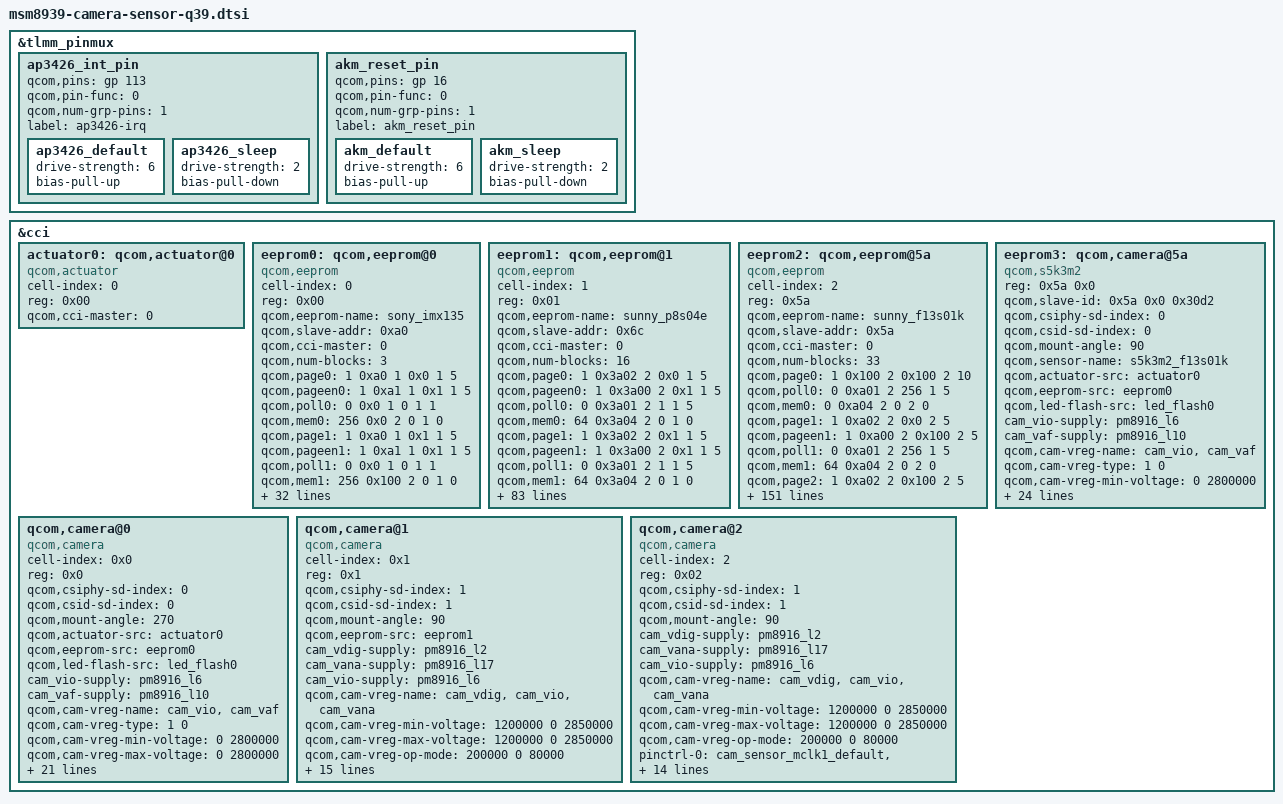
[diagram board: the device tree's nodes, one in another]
/* Copyright (c) 2017, The Linux Foundation. All rights reserved.
 *
 * This program is free software; you can redistribute it and/or modify
 * it under the terms of the GNU General Public License version 2 and
 * only version 2 as published by the Free Software Foundation.
 *
 * This program is distributed in the hope that it will be useful,
 * but WITHOUT ANY WARRANTY; without even the implied warranty of
 * MERCHANTABILITY or FITNESS FOR A PARTICULAR PURPOSE.  See the
 * GNU General Public License for more details.
 */

&tlmm_pinmux {
		ap3426_int_pin {
		qcom,pins = <&gp 113>;
		qcom,pin-func = <0>;
		qcom,num-grp-pins = <1>;
		label = "ap3426-irq";

		ap3426_default: ap3426_default {
			drive-strength = <6>;
			bias-pull-up;
			};

		ap3426_sleep: ap3426_sleep {
			drive-strength = <2>;
			bias-pull-down;
			};
		};

		akm_reset_pin {
			qcom,pins = <&gp 16>;
			qcom,pin-func = <0>;
			qcom,num-grp-pins = <1>;
			label = "akm_reset_pin";

			akm_default: akm_default {
				drive-strength = <6>;
				bias-pull-up;
			};

			akm_sleep: akm_sleep {
			drive-strength = <2>;
			bias-pull-down;
			};
		};
};

&cci {

		actuator0: qcom,actuator@0 {
			cell-index = <0>;
			reg = <0x00>;
			compatible = "qcom,actuator";
			qcom,cci-master = <0>;
		};

		eeprom0: qcom,eeprom@0 {
			cell-index = <0>;
			reg = <0x00>;
			qcom,eeprom-name = "sony_imx135";
			compatible = "qcom,eeprom";
			qcom,slave-addr = <0xa0>;
			qcom,cci-master = <0>;
			qcom,num-blocks = <3>;

			qcom,page0 = <1 0xa0 1 0x0 1 5>;
			qcom,pageen0 = <1 0xa1 1 0x1 1 5>;
			qcom,poll0 = <0 0x0 1 0 1 1>;
			qcom,mem0 = <256 0x0 2 0 1 0>;
			qcom,page1 = <1 0xa0 1 0x1 1 5>;
			qcom,pageen1 = <1 0xa1 1 0x1 1 5>;
			qcom,poll1 = <0 0x0 1 0 1 1>;
			qcom,mem1 = <256 0x100 2 0 1 0>;
			qcom,page2 = <1 0xa0 1 0x2 1 5>;
			qcom,pageen2 = <1 0xa1 1 0x1 1 5>;
			qcom,poll2 = <0 0x0 1 0 1 1>;
			qcom,mem2 = <23 0x200 2 0 1 0>;

			cam_vio-supply = <&pm8916_l2>;
			qcom,cam-vreg-name = "cam_vio";
			qcom,cam-vreg-min-voltage = <0>;
			qcom,cam-vreg-max-voltage = <0>;
			qcom,cam-vreg-op-mode = <0>;
			pinctrl-names = "cam_default", "cam_suspend";
			pinctrl-0 = <&cam_sensor_mclk0_default &cam_sensor_rear_default>;
			pinctrl-1 = <&cam_sensor_mclk0_sleep &cam_sensor_rear_sleep>;
			gpios = <&msm_gpio 26 0>,
				<&msm_gpio 35 0>,
				<&msm_gpio 2 0>,
				<&msm_gpio 3 0>;
			qcom,gpio-reset = <1>;
			qcom,gpio-vana = <2>;
			qcom,gpio-vdig = <3>;
			qcom,gpio-req-tbl-num = <0 1 2 3>;
			qcom,gpio-req-tbl-flags = <1 0 0 0>;
			qcom,gpio-req-tbl-label = "CAMIF_MCLK0",
				"CAM_RESET1",
				"CAM_VANA",
				"CAM_VDIG";

			qcom,cam-power-seq-type = "sensor_gpio",
				"sensor_gpio", "sensor_vreg",
				"sensor_clk", "sensor_gpio";
			qcom,cam-power-seq-val = "sensor_gpio_vana",
				"sensor_gpio_vdig", "cam_vio",
				"sensor_cam_mclk", "sensor_gpio_reset";
			qcom,cam-power-seq-cfg-val = <1 1 1 24000000 1>;
			qcom,cam-power-seq-delay = <1 1 5 5 10>;
			status = "ok";
			clocks = <&clock_gcc clk_mclk0_clk_src>,
				<&clock_gcc clk_gcc_camss_mclk0_clk>;
			clock-names = "cam_src_clk", "cam_clk";
		};

		eeprom1: qcom,eeprom@1 {
			cell-index = <1>;
			reg = <0x01>;
			qcom,eeprom-name = "sunny_p8s04e";
			compatible = "qcom,eeprom";
			qcom,slave-addr = <0x6c>;
			qcom,cci-master = <0>;

			qcom,num-blocks = <16>;
			qcom,page0 = <1 0x3a02 2 0x0 1 5>;
			qcom,pageen0 = <1 0x3a00 2 0x1 1 5>;
			qcom,poll0 = <0 0x3a01 2 1 1 5>;
			qcom,mem0 = <64 0x3a04 2 0 1 0>;
			qcom,page1 = <1 0x3a02 2 0x1 1 5>;
			qcom,pageen1 = <1 0x3a00 2 0x1 1 5>;
			qcom,poll1 = <0 0x3a01 2 1 1 5>;
			qcom,mem1 = <64 0x3a04 2 0 1 0>;
			qcom,page2 = <1 0x3a02 2 0x2 1 5>;
			qcom,pageen2 = <1 0x3a00 2 0x1 1 5>;
			qcom,poll2 = <0 0x3a01 2 1 1 5>;
			qcom,mem2 = <64 0x3a04 2 0 1 0>;
			qcom,page3 = <1 0x3a02 2 0x3 1 5>;
			qcom,pageen3 = <1 0x3a00 2 0x1 1 5>;
			qcom,poll3 = <0 0x3a01 2 1 1 5>;
			qcom,mem3 = <64 0x3a04 2 0 1 0>;
			qcom,page4 = <1 0x3a02 2 0x4 1 5>;
			qcom,pageen4 = <1 0x3a00 2 0x1 1 5>;
			qcom,poll4 = <0 0x3a01 2 1 1 5>;
			qcom,mem4 = <64 0x3a04 2 0 1 0>;
			qcom,page5 = <1 0x3a02 2 0x5 1 5>;
			qcom,pageen5 = <1 0x3a00 2 0x1 1 5>;
			qcom,poll5 = <0 0x3a01 2 1 1 5>;
			qcom,mem5 = <64 0x3a04 2 0 1 0>;
			qcom,page6 = <1 0x3a02 2 0x6 1 5>;
			qcom,pageen6 = <1 0x3a00 2 0x1 1 5>;
			qcom,poll6 = <0 0x3a01 2 1 1 5>;
			qcom,mem6 = <64 0x3a04 2 0 1 0>;
			qcom,page7 = <1 0x3a02 2 0x7 1 5>;
			qcom,pageen7 = <1 0x3a00 2 0x1 1 5>;
			qcom,poll7 = <0 0x3a01 2 1 1 5>;
			qcom,mem7 = <64 0x3a04 2 0 1 0>;
			qcom,page8 = <1 0x3a02 2 0x8 1 5>;
			qcom,pageen8 = <1 0x3a00 2 0x1 1 5>;
			qcom,poll8 = <0 0x3a01 2 1 1 5>;
			qcom,mem8 = <64 0x3a04 2 0 1 0>;
			qcom,page9 = <1 0x3a02 2 0x9 1 5>;
			qcom,pageen9 = <1 0x3a00 2 0x1 1 5>;
			qcom,poll9 = <0 0x3a01 2 1 1 5>;
			qcom,mem9 = <64 0x3a04 2 0x0 1 0>;
			qcom,page10 = <1 0x3a02 2 0xa 1 5>;
			qcom,pageen10 = <1 0x3a00 2 0x1 1 5>;
			qcom,poll10 = <0 0x3a01 2 1 1 5>;
			qcom,mem10 = <64 0x3a04 2 0 1 0>;
			qcom,page11 = <1 0x3a02 2 0xb 1 5>;
			qcom,pageen11 = <1 0x3a00 2 0x1 1 5>;
			qcom,poll11 = <0 0x3a01 2 1 1 5>;
			qcom,mem11 = <64 0x3a04 2 0 1 0>;
			qcom,page12 = <1 0x3a02 2 0xc 1 5>;
			qcom,pageen12 = <1 0x3a00 2 0x1 1 5>;
			qcom,poll12 = <0 0x3a01 2 1 1 5>;
			qcom,mem12 = <64 0x3a04 2 0 1 0>;
			qcom,page13 = <1 0x3a02 2 0xd 1 5>;
			qcom,pageen13 = <1 0x3a00 2 0x1 1 5>;
			qcom,poll13 = <0 0x3a01 2 1 1 5>;
			qcom,mem13 = <64 0x3a04 2 0 1 0>;
			qcom,page14 = <1 0x3a02 2 0xe 1 5>;
			qcom,pageen14 = <1 0x3a00 2 0x1 1 5>;
			qcom,poll14 = <0 0x3a01 2 1 1 5>;
			qcom,mem14 = <64 0x3a04 2 0 1 0>;
			qcom,page15 = <1 0x3a02 2 0xf 1 5>;
			qcom,pageen15 = <1 0x3a00 2 0x1 1 5>;
			qcom,poll15 = <0 0x3a01 2 1 1 5>;
			qcom,mem15 = <64 0x3a04 2 0 1 0>;

			cam_vdig-supply = <&pm8916_l2>;
			cam_vana-supply = <&pm8916_l17>;
			cam_vio-supply = <&pm8916_l6>;
			qcom,cam-vreg-name = "cam_vdig", "cam_vio", "cam_vana";
			qcom,cam-vreg-min-voltage = <1200000 0 2850000>;
			qcom,cam-vreg-max-voltage = <1200000 0 2850000>;
			qcom,cam-vreg-op-mode = <200000 0 80000>;
			pinctrl-names = "cam_default", "cam_suspend";
			pinctrl-0 = <&cam_sensor_mclk1_default &cam_sensor_front_default>;
			pinctrl-1 = <&cam_sensor_mclk1_sleep &cam_sensor_front_sleep>;
			gpios = <&msm_gpio 0x1b 0x0>,
				<&msm_gpio 0x1c 0x0>;
			qcom,gpio-reset = <1>;
			qcom,gpio-req-tbl-num = <0 1>;
			qcom,gpio-req-tbl-flags = <1 0>;
			qcom,gpio-req-tbl-label = "CAMIF_MCLK1",
				"CAM_RESET";

			qcom,cam-power-seq-type = "sensor_vreg",
				"sensor_vreg", "sensor_vreg",
				"sensor_clk", "sensor_gpio";
			qcom,cam-power-seq-val = "cam_vdig",
				"cam_vana", "cam_vio",
				"sensor_cam_mclk", "sensor_gpio_reset";
			qcom,cam-power-seq-cfg-val = <1 1 1 24000000 1>;
			qcom,cam-power-seq-delay = <10 10 10 5 10>;
			clocks = <&clock_gcc clk_mclk1_clk_src>,
				<&clock_gcc clk_gcc_camss_mclk1_clk>;
			clock-names = "cam_src_clk", "cam_clk";
		};

		eeprom2: qcom,eeprom@5a {
			cell-index = <2>;
			reg = <0x5a>;
			qcom,eeprom-name = "sunny_f13s01k";
			compatible = "qcom,eeprom";
			qcom,slave-addr = <0x5a>;
			qcom,cci-master = <0>;

			qcom,num-blocks = <33>;
			qcom,page0 = <1 0x100 2 0x100 2 10>;
			qcom,poll0 = <0 0xa01 2 256 1 5>;
			qcom,mem0 = <0 0xa04 2 0 2 0>;
			qcom,page1 = <1 0xa02 2 0x0 2 5>;
			qcom,pageen1 = <1 0xa00 2 0x100 2 5>;
			qcom,poll1 = <0 0xa01 2 256 1 5>;
			qcom,mem1 = <64 0xa04 2 0 2 0>;
			qcom,page2 = <1 0xa02 2 0x100 2 5>;
			qcom,pageen2 = <1 0xa00 2 0x100 2 5>;
			qcom,poll2 = <0 0xa01 2 1 1 5>;
			qcom,mem2 = <64 0xa04 2 0 2 0>;
			qcom,page3 = <1 0xa02 2 0x200 2 5>;
			qcom,pageen3 = <1 0xa00 2 0x100 2 5>;
			qcom,poll3 = <0 0xa01 2 256 1 5>;
			qcom,mem3 = <64 0xa04 2 0 2 0>;
			qcom,page4 = <1 0xa02 2 0x300 2 5>;
			qcom,pageen4 = <1 0xa00 2 0x100 2 5>;
			qcom,poll4 = <0 0xa01 2 1 1 5>;
			qcom,mem4 = <64 0xa04 2 0 2 0>;
			qcom,page5 = <1 0xa02 2 0x400 2 5>;
			qcom,pageen5 = <1 0xa00 2 0x100 2 5>;
			qcom,poll5 = <0 0xa01 2 256 1 5>;
			qcom,mem5 = <64 0xa04 2 0 2 0>;
			qcom,page6 = <1 0xa02 2 0x500 2 5>;
			qcom,pageen6 = <1 0xa00 2 0x100 2 5>;
			qcom,poll6 = <0 0xa01 2 1 1 5>;
			qcom,mem6 = <64 0xa04 2 0 2 0>;
			qcom,page7 = <1 0xa02 2 0x600 2 5>;
			qcom,pageen7 = <1 0xa00 2 0x100 2 5>;
			qcom,poll7 = <0 0xa01 2 1 1 5>;
			qcom,mem7 = <64 0xa04 2 0 2 0>;
			qcom,page8 = <1 0xa02 2 0x700 2 5>;
			qcom,pageen8 = <1 0xa00 2 0x100 2 5>;
			qcom,poll8 = <0 0xa01 2 1 1 5>;
			qcom,mem8 = <64 0xa04 2 0 2 0>;
			qcom,page9 = <1 0xa02 2 0x800 2 5>;
			qcom,pageen9 = <1 0xa00 2 0x100 2 5>;
			qcom,poll9 = <0 0xa01 2 1 1 5>;
			qcom,mem9 = <64 0xa04 2 0 2 0>;
			qcom,page10 = <1 0xa02 2 0x900 2 5>;
			qcom,pageen10 = <1 0xa00 2 0x100 2 5>;
			qcom,poll10 = <0 0xa01 2 1 1 5>;
			qcom,mem10 = <64 0xa04 2 0 2 0>;
			qcom,page11 = <1 0xa02 2 0xa00 2 5>;
			qcom,pageen11 = <1 0xa00 2 0x100 2 5>;
			qcom,poll11 = <0 0xa01 2 1 1 5>;
			qcom,mem11 = <64 0xa04 2 0 2 0>;
			qcom,page12 = <1 0xa02 2 0xb00 2 5>;
			qcom,pageen12 = <1 0xa00 2 0x100 2 5>;
			qcom,poll12 = <0 0xa01 2 1 1 5>;
			qcom,mem12 = <64 0xa04 2 0 2 0>;
			qcom,page13 = <1 0xa02 2 0xc00 2 5>;
			qcom,pageen13 = <1 0xa00 2 0x100 2 5>;
			qcom,poll13 = <0 0xa01 2 1 1 5>;
			qcom,mem13 = <64 0xa04 2 0 2 0>;
			qcom,page14 = <1 0xa02 2 0xd00 2 5>;
			qcom,pageen14 = <1 0xa00 2 0x100 2 5>;
			qcom,poll14 = <0 0xa01 2 1 1 5>;
			qcom,mem14 = <64 0xa04 2 0 2 0>;
			qcom,page15 = <1 0xa02 2 0xe00 2 5>;
			qcom,pageen15 = <1 0xa00 2 0x100 2 5>;
			qcom,poll15 = <0 0xa01 2 1 1 5>;
			qcom,mem15 = <64 0xa04 2 0 2 0>;
			qcom,page16 = <1 0xa02 2 0xf00 2 5>;
			qcom,pageen16 = <1 0xa00 2 0x100 2 5>;
			qcom,poll16 = <0 0xa01 2 1 1 5>;
			qcom,mem16 = <64 0xa04 2 0 2 0>;
			qcom,page17 = <1 0xa02 2 0x1000 2 5>;
			qcom,pageen17 = <1 0xa00 2 0x100 2 5>;
			qcom,poll17 = <0 0xa01 2 1 1 5>;
			qcom,mem17 = <64 0xa04 2 0 2 0>;
			qcom,page18 = <1 0xa02 2 0x1100 2 5>;
			qcom,pageen18 = <1 0xa00 2 0x100 2 5>;
			qcom,poll18 = <0 0xa01 2 1 1 5>;
			qcom,mem18 = <64 0xa04 2 0 2 0>;
			qcom,page19 = <1 0xa02 2 0x1200 2 5>;
			qcom,pageen19 = <1 0xa00 2 0x100 2 5>;
			qcom,poll19 = <0 0xa01 2 1 1 5>;
			qcom,mem19 = <64 0xa04 2 0 2 0>;
			qcom,page20 = <1 0xa02 2 0x1300 2 5>;
			qcom,pageen20 = <1 0xa00 2 0x100 2 5>;
			qcom,poll20 = <0 0xa01 2 1 1 5>;
			qcom,mem20 = <64 0xa04 2 0 2 0>;
			qcom,page21 = <1 0xa02 2 0x1400 2 5>;
			qcom,pageen21 = <1 0xa00 2 0x100 2 5>;
			qcom,poll21 = <0 0xa01 2 1 1 5>;
			qcom,mem21 = <64 0xa04 2 0 2 0>;
			qcom,page22 = <1 0xa02 2 0x1500 2 5>;
			qcom,pageen22 = <1 0xa00 2 0x100 2 5>;
			qcom,poll22 = <0 0xa01 2 1 1 5>;
			qcom,mem22 = <64 0xa04 2 0 2 0>;
			qcom,page23 = <1 0xa02 2 0x1600 2 5>;
			qcom,pageen23 = <1 0xa00 2 0x100 2 5>;
			qcom,poll23 = <0 0xa01 2 1 1 5>;
			qcom,mem23 = <64 0xa04 2 0 2 0>;
			qcom,page24 = <1 0xa02 2 0x1700 2 5>;
			qcom,pageen24 = <1 0xa00 2 0x100 2 5>;
			qcom,poll24 = <0 0xa01 2 1 1 5>;
			qcom,mem24 = <64 0xa04 2 0 2 0>;
			qcom,page25 = <1 0xa02 2 0x1800 2 5>;
			qcom,pageen25 = <1 0xa00 2 0x100 2 5>;
			qcom,poll25 = <0 0xa01 2 1 1 5>;
			qcom,mem25 = <64 0xa04 2 0 2 0>;
			qcom,page26 = <1 0xa02 2 0x1900 2 5>;
			qcom,pageen26 = <1 0xa00 2 0x100 2 5>;
			qcom,poll26 = <0 0xa01 2 1 1 5>;
			qcom,mem26 = <64 0xa04 2 0 2 0>;
			qcom,page27 = <1 0xa02 2 0x1a00 2 5>;
			qcom,pageen27 = <1 0xa00 2 0x100 2 5>;
			qcom,poll27 = <0 0xa01 2 1 1 5>;
			qcom,mem27 = <64 0xa04 2 0 2 0>;
			qcom,page28 = <1 0xa02 2 0x1b00 2 5>;
			qcom,pageen28 = <1 0xa00 2 0x100 2 5>;
			qcom,poll28 = <0 0xa01 2 1 1 5>;
			qcom,mem28 = <64 0xa04 2 0 2 0>;
			qcom,page29 = <1 0xa02 2 0x1c00 2 5>;
			qcom,pageen29 = <1 0xa00 2 0x100 2 5>;
			qcom,poll29 = <0 0xa01 2 1 1 5>;
			qcom,mem29 = <64 0xa04 2 0 2 0>;
			qcom,page30 = <1 0xa02 2 0x1d00 2 5>;
			qcom,pageen30 = <1 0xa00 2 0x100 2 5>;
			qcom,poll30 = <0 0xa01 2 1 1 5>;
			qcom,mem30 = <64 0xa04 2 0 2 0>;
			qcom,page31 = <1 0xa02 2 0x1e00 2 5>;
			qcom,pageen31 = <1 0xa00 2 0x100 2 5>;
			qcom,poll31 = <0 0xa01 2 1 1 5>;
			qcom,mem31 = <64 0xa04 2 0 2 0>;
			qcom,page32 = <1 0xa02 2 0x1f00 2 5>;
			qcom,pageen32 = <1 0xa00 2 0x100 2 5>;
			qcom,poll32 = <0 0xa01 2 1 1 5>;
			qcom,mem32 = <64 0xa04 2 0 2 0>;
			cam_vio-supply = <&pm8916_l6>;
			qcom,cam-vreg-name = "cam_vio";
			qcom,cam-vreg-min-voltage = <0>;
			qcom,cam-vreg-max-voltage = <0>;
			qcom,cam-vreg-op-mode = <0>;
			pinctrl-names = "cam_default", "cam_suspend";
			pinctrl-0 = <&cam_sensor_mclk1_default &cam_sensor_front_default>;
			pinctrl-1 = <&cam_sensor_mclk1_sleep &cam_sensor_front_sleep>;
			gpios = <&msm_gpio 26 0>,
				<&msm_gpio 35 0>,
				<&msm_gpio 2 0>,
				<&msm_gpio 3 0>;
			qcom,gpio-reset = <1>;
			qcom,gpio-vana = <2>;
			qcom,gpio-vdig = <3>;
			qcom,gpio-req-tbl-num = <0 1 2 3>;
			qcom,gpio-req-tbl-flags = <1 0 0 0>;
			qcom,gpio-req-tbl-label = "CAMIF_MCLK0",
				"CAM_RESET1",
				"CAM_VANA",
				"CAM_VDIG";

			qcom,cam-power-seq-type = "sensor_gpio",
				"sensor_gpio", "sensor_vreg",
				"sensor_clk", "sensor_gpio";
			qcom,cam-power-seq-val = "sensor_gpio_vana",
				"sensor_gpio_vdig", "cam_vio",
				"sensor_cam_mclk", "sensor_gpio_reset";
			qcom,cam-power-seq-cfg-val = <1 1 1 24000000 1>;
			qcom,cam-power-seq-delay = <1 1 5 5 10>;
			status = "ok";
			clocks = <&clock_gcc clk_mclk0_clk_src>,
				<&clock_gcc clk_gcc_camss_mclk0_clk>;
			clock-names = "cam_src_clk", "cam_clk";
		};

		eeprom3: qcom,camera@5a {
			compatible = "qcom,s5k3m2";
			reg = <0x5a 0x0>;
			qcom,slave-id = <0x5a 0x0 0x30d2>;
			qcom,csiphy-sd-index = <0>;
			qcom,csid-sd-index = <0>;
			qcom,mount-angle = <90>;
			qcom,sensor-name = "s5k3m2_f13s01k";
			qcom,actuator-src = <&actuator0>;
			qcom,eeprom-src = <&eeprom0>;
			qcom,led-flash-src = <&led_flash0>;
			cam_vio-supply = <&pm8916_l6>;
			cam_vaf-supply = <&pm8916_l10>;
			qcom,cam-vreg-name = "cam_vio", "cam_vaf";
			qcom,cam-vreg-type = <1 0>;
			qcom,cam-vreg-min-voltage = <0 2800000>;
			qcom,cam-vreg-max-voltage = <0 2800000>;
			qcom,cam-vreg-op-mode = <0 2800000>;
			pinctrl-names = "cam_default", "cam_suspend";
			pinctrl-0 = <&cam_sensor_mclk0_default &cam_sensor_rear_default>;
			pinctrl-1 = <&cam_sensor_mclk0_sleep &cam_sensor_rear_sleep>;
			gpios = <&msm_gpio 26 0>,
				<&msm_gpio 35 0>,
				<&msm_gpio 120 0>,
				<&msm_gpio 2 0>,
				<&msm_gpio 3 0>;
			qcom,gpio-reset = <1>;
			qcom,gpio-af-pwdm = <2>;
			qcom,gpio-vana = <3>;
			qcom,gpio-vdig = <4>;
			qcom,gpio-req-tbl-num = <0 1 2 3 4>;
			qcom,gpio-req-tbl-flags = <1 0 0 0 0>;
			qcom,csi-lane-assign = <0x4320>;
			qcom,csi-lane-mask = <0x1f>;
			qcom,gpio-req-tbl-label = "CAMIF_MCLK0",
				"CAM_RESET1",
				"MCAM_AF_PWDM",
				"CAM_VANA",
				"CAM_VDIG";
			qcom,sensor-position = <0>;
			qcom,sensor-mode = <0>;
			qcom,cci-master = <0>;
			qcom,mclk-24000000;
			status = "ok";
			clocks = <&clock_gcc clk_mclk0_clk_src>,
				<&clock_gcc clk_gcc_camss_mclk0_clk>;
			clock-names = "cam_src_clk", "cam_clk";
			};

		qcom,camera@0 {
			cell-index = <0x0>;
			compatible = "qcom,camera";
			reg = <0x0>;
			qcom,csiphy-sd-index = <0>;
			qcom,csid-sd-index = <0>;
			qcom,mount-angle = <270>;
			qcom,actuator-src = <&actuator0>;
			qcom,eeprom-src = <&eeprom0>;
			qcom,led-flash-src = <&led_flash0>;
			cam_vio-supply = <&pm8916_l6>;
			cam_vaf-supply = <&pm8916_l10>;
			qcom,cam-vreg-name = "cam_vio", "cam_vaf";
			qcom,cam-vreg-type = <1 0>;
			qcom,cam-vreg-min-voltage = <0 2800000>;
			qcom,cam-vreg-max-voltage = <0 2800000>;
			qcom,cam-vreg-op-mode = <0 2800000>;
			pinctrl-names = "cam_default", "cam_suspend";
			pinctrl-0 = <&cam_sensor_mclk0_default &cam_sensor_rear_default>;
			pinctrl-1 = <&cam_sensor_mclk0_sleep &cam_sensor_rear_sleep>;
			gpios = <&msm_gpio 26 0x0>,
				<&msm_gpio 35 0x0>,
				<&msm_gpio 120 0x0>,
				<&msm_gpio 2 0x0>,
				<&msm_gpio 3 0x0>;
			qcom,gpio-reset = <0x1>;
			qcom,gpio-af-pwdm = <0x2>;
			qcom,gpio-vana = <0x3>;
			qcom,gpio-vdig = <0x4>;
			qcom,gpio-req-tbl-num = <0x0 0x1 0x2 0x3 0x4>;
			qcom,gpio-req-tbl-flags = <0x1 0x0 0x0 0x0 0x0>;
			qcom,gpio-req-tbl-label = "CAMIF_MCLK0",
				"CAM_RESET1",
				"MCAM_AF_PWDM",
				"CAM_VANA",
				"CAM_VDIG";
			qcom,sensor-position = <0x0>;
			qcom,sensor-mode = <0x0>;
			qcom,cci-master = <0x0>;
			qcom,mclk-24000000;
			status = "ok";
			clocks = <&clock_gcc clk_mclk0_clk_src>,
				<&clock_gcc clk_gcc_camss_mclk0_clk>;
			clock-names = "cam_src_clk", "cam_clk";
		};

		qcom,camera@1 {
			cell-index = <0x1>;
			compatible = "qcom,camera";
			reg = <0x1>;
			qcom,csiphy-sd-index = <1>;
			qcom,csid-sd-index = <1>;
			qcom,mount-angle = <90>;
			qcom,eeprom-src = <&eeprom1>;
			cam_vdig-supply = <&pm8916_l2>;
			cam_vana-supply = <&pm8916_l17>;
			cam_vio-supply = <&pm8916_l6>;
			qcom,cam-vreg-name = "cam_vdig", "cam_vio", "cam_vana";
			qcom,cam-vreg-min-voltage = <1200000 0 2850000>;
			qcom,cam-vreg-max-voltage = <1200000 0 2850000>;
			qcom,cam-vreg-op-mode = <200000 0 80000>;
			pinctrl-names = "cam_default", "cam_suspend";
			pinctrl-0 = <&cam_sensor_mclk1_default &cam_sensor_front_default>;
			pinctrl-1 = <&cam_sensor_mclk1_sleep &cam_sensor_front_sleep>;
			gpios = <&msm_gpio 27 0>,
				<&msm_gpio 28 0>;
			qcom,gpio-reset = <1>;
			qcom,gpio-req-tbl-num = <0 1>;
			qcom,gpio-req-tbl-flags = <1 0>;
			qcom,gpio-req-tbl-label = "CAMIF_MCLK1",
				"SCAM_RESET";
			qcom,sensor-position = <1>;
			qcom,sensor-mode = <0>;
			qcom,cci-master = <0>;
			status = "ok";
			clocks = <&clock_gcc clk_mclk1_clk_src>,
				<&clock_gcc clk_gcc_camss_mclk1_clk>;
			clock-names = "cam_src_clk", "cam_clk";
		};

		qcom,camera@2 {
			cell-index = <2>;
			compatible = "qcom,camera";
			reg = <0x02>;
			qcom,csiphy-sd-index = <1>;
			qcom,csid-sd-index = <1>;
			qcom,mount-angle = <90>;
			cam_vdig-supply = <&pm8916_l2>;
			cam_vana-supply = <&pm8916_l17>;
			cam_vio-supply = <&pm8916_l6>;
			qcom,cam-vreg-name = "cam_vdig", "cam_vio", "cam_vana";
			qcom,cam-vreg-min-voltage = <1200000 0 2850000>;
			qcom,cam-vreg-max-voltage = <1200000 0 2850000>;
			qcom,cam-vreg-op-mode = <200000 0 80000>;
			pinctrl-names = "cam_default", "cam_suspend";
			pinctrl-0 = <&cam_sensor_mclk1_default &cam_sensor_front_default>;
			pinctrl-1 = <&cam_sensor_mclk1_sleep &cam_sensor_front_sleep>;
			gpios = <&msm_gpio 27 0>,
				<&msm_gpio 28 0>;
			qcom,gpio-reset = <1>;
			qcom,gpio-req-tbl-num = <0 1>;
			qcom,gpio-req-tbl-flags = <1 0>;
			qcom,gpio-req-tbl-label = "CAMIF_MCLK1",
				"SCAM_RESET";
			qcom,sensor-position = <1>;
			qcom,sensor-mode = <0>;
			qcom,cci-master = <0>;
			status = "ok";
			clocks = <&clock_gcc clk_mclk1_clk_src>,
				<&clock_gcc clk_gcc_camss_mclk1_clk>;
			clock-names = "cam_src_clk", "cam_clk";
		};
	};
